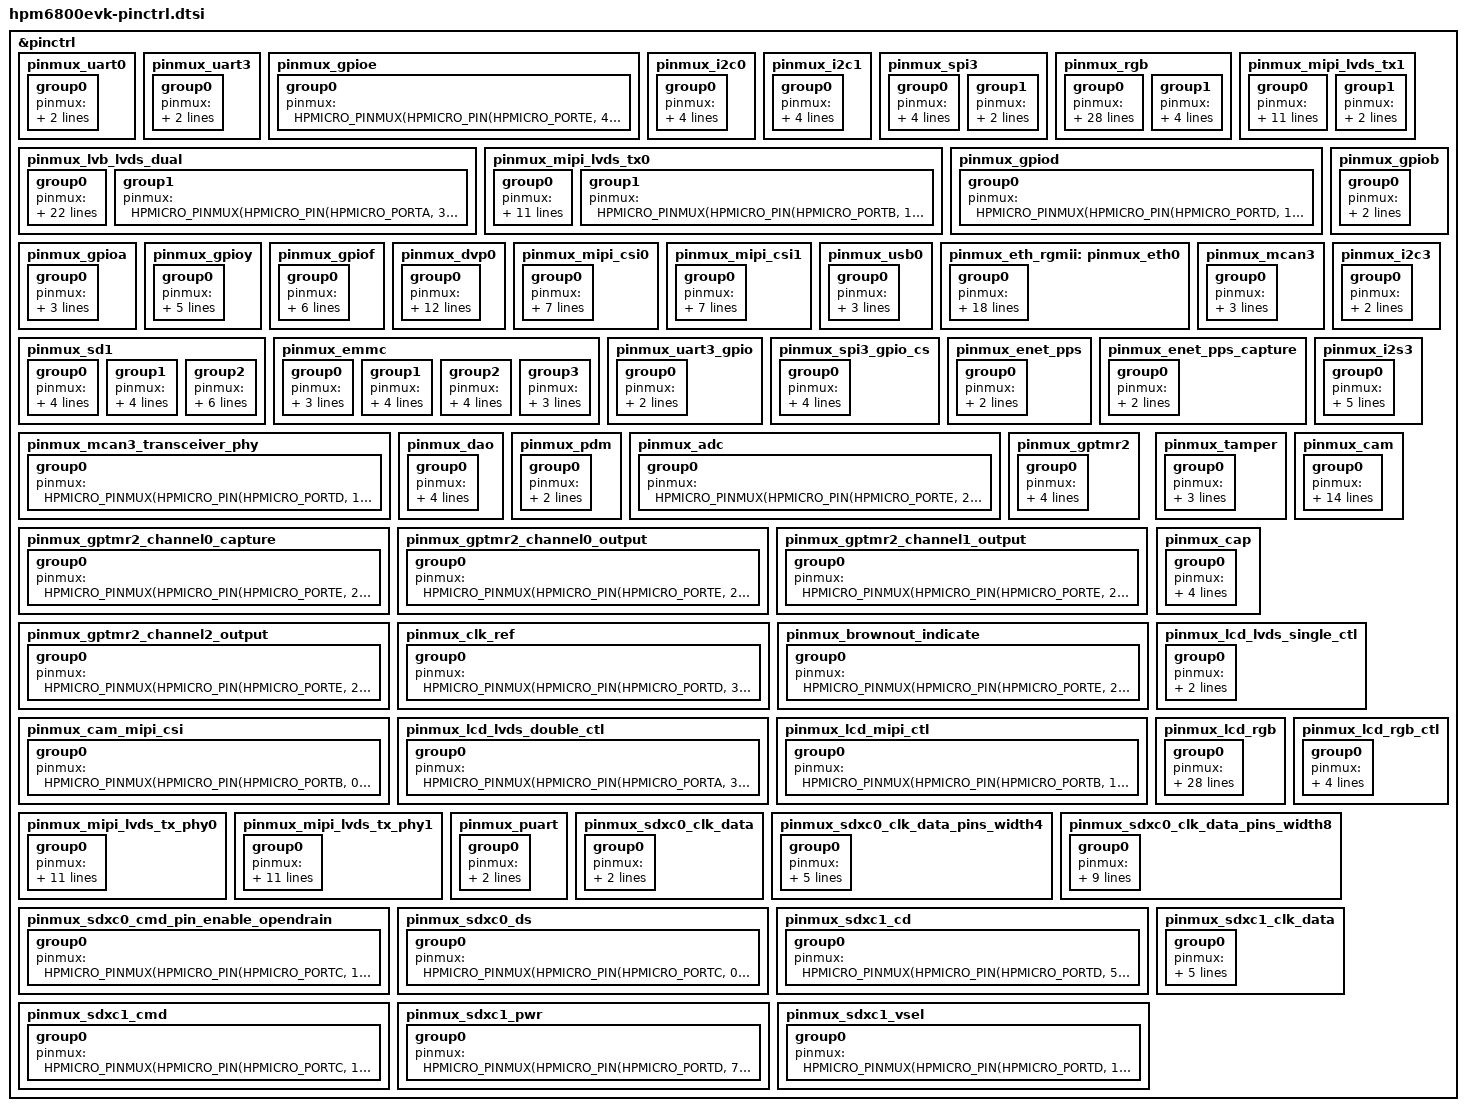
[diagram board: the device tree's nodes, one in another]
/*
* Copyright 2024-2026 HPMicro
* SPDX-License-Identifier: Apache-2.0
*/

#include "dt-bindings/pinctrl/hpmicro-pinctrl-common.h"

&pinctrl {
	pinmux_uart0: pinmux_uart0 {
		group0 {
			pinmux = <HPMICRO_PINMUX(HPMICRO_PIN(HPMICRO_PORTA, 0), IOC_TYPE_IOC, 0, 2)>,
				<HPMICRO_PINMUX(HPMICRO_PIN(HPMICRO_PORTA, 1), IOC_TYPE_IOC, 0, 2)>;
		};
	};

	pinmux_uart3: pinmux_uart3 {
		group0 {
			pinmux = <HPMICRO_PINMUX(HPMICRO_PIN(HPMICRO_PORTE, 14), IOC_TYPE_IOC, 0, 2)>,
				<HPMICRO_PINMUX(HPMICRO_PIN(HPMICRO_PORTE, 15), IOC_TYPE_IOC, 0, 2)>;
		};
	};

	pinmux_gpioe: pinmux_gpioe {
		group0 {
			pinmux = <HPMICRO_PINMUX(HPMICRO_PIN(HPMICRO_PORTE, 4), IOC_TYPE_IOC, 0, 0)>;
		};
	};

	pinmux_i2c0: pinmux_i2c0 {
		group0 {
			pinmux = <HPMICRO_PINMUX(HPMICRO_PIN(HPMICRO_PORTF, 9), IOC_TYPE_IOC, 0, 4)>,
				<HPMICRO_PINMUX(HPMICRO_PIN(HPMICRO_PORTF, 8), IOC_TYPE_IOC, 0, 4)>;
			drive-open-drain;
			input-enable;
		};
	};

	pinmux_i2c1: pinmux_i2c1 {
		group0 {
			pinmux = <HPMICRO_PINMUX(HPMICRO_PIN(HPMICRO_PORTE, 12), IOC_TYPE_IOC, 0, 4)>,
				<HPMICRO_PINMUX(HPMICRO_PIN(HPMICRO_PORTE, 13), IOC_TYPE_IOC, 0, 4)>;
			drive-open-drain;
			input-enable;
		};
	};

	pinmux_spi3: pinmux_spi3 {
		group0 {
			pinmux = <HPMICRO_PINMUX(HPMICRO_PIN(HPMICRO_PORTE, 5), IOC_TYPE_IOC, 0, 5)>,
				<HPMICRO_PINMUX(HPMICRO_PIN(HPMICRO_PORTE, 6), IOC_TYPE_IOC, 0, 5)>,
				<HPMICRO_PINMUX(HPMICRO_PIN(HPMICRO_PORTE, 7), IOC_TYPE_IOC, 0, 5)>;
			input-enable;
		};

		group1 {
			pinmux = <HPMICRO_PINMUX(HPMICRO_PIN(HPMICRO_PORTE, 4), IOC_TYPE_IOC, 0, 0)>;
			bias-pull-up;
		};
	};

	pinmux_rgb: pinmux_rgb {
		group0 {
			pinmux = <HPMICRO_PINMUX(HPMICRO_PIN(HPMICRO_PORTA, 10), IOC_TYPE_IOC, 0, 20)>,
				<HPMICRO_PINMUX(HPMICRO_PIN(HPMICRO_PORTA, 11), IOC_TYPE_IOC, 0, 20)>,
				<HPMICRO_PINMUX(HPMICRO_PIN(HPMICRO_PORTA, 12), IOC_TYPE_IOC, 0, 20)>,
				<HPMICRO_PINMUX(HPMICRO_PIN(HPMICRO_PORTA, 13), IOC_TYPE_IOC, 0, 20)>,
				<HPMICRO_PINMUX(HPMICRO_PIN(HPMICRO_PORTA, 15), IOC_TYPE_IOC, 0, 20)>,
				<HPMICRO_PINMUX(HPMICRO_PIN(HPMICRO_PORTA, 16), IOC_TYPE_IOC, 0, 20)>,
				<HPMICRO_PINMUX(HPMICRO_PIN(HPMICRO_PORTA, 17), IOC_TYPE_IOC, 0, 20)>,
				<HPMICRO_PINMUX(HPMICRO_PIN(HPMICRO_PORTA, 18), IOC_TYPE_IOC, 0, 20)>,
				<HPMICRO_PINMUX(HPMICRO_PIN(HPMICRO_PORTA, 19), IOC_TYPE_IOC, 0, 20)>,
				<HPMICRO_PINMUX(HPMICRO_PIN(HPMICRO_PORTA, 20), IOC_TYPE_IOC, 0, 20)>,
				<HPMICRO_PINMUX(HPMICRO_PIN(HPMICRO_PORTA, 28), IOC_TYPE_IOC, 0, 20)>,
				<HPMICRO_PINMUX(HPMICRO_PIN(HPMICRO_PORTA, 30), IOC_TYPE_IOC, 0, 20)>,
				<HPMICRO_PINMUX(HPMICRO_PIN(HPMICRO_PORTA, 31), IOC_TYPE_IOC, 0, 20)>,
				<HPMICRO_PINMUX(HPMICRO_PIN(HPMICRO_PORTB, 0), IOC_TYPE_IOC, 0, 20)>,
				<HPMICRO_PINMUX(HPMICRO_PIN(HPMICRO_PORTB, 1), IOC_TYPE_IOC, 0, 20)>,
				<HPMICRO_PINMUX(HPMICRO_PIN(HPMICRO_PORTB, 2), IOC_TYPE_IOC, 0, 20)>,
				<HPMICRO_PINMUX(HPMICRO_PIN(HPMICRO_PORTB, 3), IOC_TYPE_IOC, 0, 20)>,
				<HPMICRO_PINMUX(HPMICRO_PIN(HPMICRO_PORTB, 4), IOC_TYPE_IOC, 0, 20)>,
				<HPMICRO_PINMUX(HPMICRO_PIN(HPMICRO_PORTB, 5), IOC_TYPE_IOC, 0, 20)>,
				<HPMICRO_PINMUX(HPMICRO_PIN(HPMICRO_PORTB, 6), IOC_TYPE_IOC, 0, 20)>,
				<HPMICRO_PINMUX(HPMICRO_PIN(HPMICRO_PORTB, 7), IOC_TYPE_IOC, 0, 20)>,
				<HPMICRO_PINMUX(HPMICRO_PIN(HPMICRO_PORTB, 8), IOC_TYPE_IOC, 0, 20)>,
				<HPMICRO_PINMUX(HPMICRO_PIN(HPMICRO_PORTB, 9), IOC_TYPE_IOC, 0, 20)>,
				<HPMICRO_PINMUX(HPMICRO_PIN(HPMICRO_PORTB, 10), IOC_TYPE_IOC, 0, 20)>,
				<HPMICRO_PINMUX(HPMICRO_PIN(HPMICRO_PORTB, 11), IOC_TYPE_IOC, 0, 20)>,
				<HPMICRO_PINMUX(HPMICRO_PIN(HPMICRO_PORTB, 12), IOC_TYPE_IOC, 0, 20)>,
				<HPMICRO_PINMUX(HPMICRO_PIN(HPMICRO_PORTB, 13), IOC_TYPE_IOC, 0, 20)>,
				<HPMICRO_PINMUX(HPMICRO_PIN(HPMICRO_PORTB, 14), IOC_TYPE_IOC, 0, 20)>;
		};

		group1 {
			pinmux = <HPMICRO_PINMUX(HPMICRO_PIN(HPMICRO_PORTA, 9), IOC_TYPE_IOC, 0, 0)>,
				<HPMICRO_PINMUX(HPMICRO_PIN(HPMICRO_PORTA, 14), IOC_TYPE_IOC, 0, 0)>,
				<HPMICRO_PINMUX(HPMICRO_PIN(HPMICRO_PORTY, 5), IOC_TYPE_IOC, 0, 0)>,
				<HPMICRO_PINMUX(HPMICRO_PIN(HPMICRO_PORTY, 5), IOC_TYPE_PIOC, 0, 3)>;
		};
	};

	pinmux_lvb_lvds_dual: pinmux_lvb_lvds_dual {
		group0 {
			pinmux = <HPMICRO_PINMUX(HPMICRO_PIN(HPMICRO_PORTB, 4), IOC_TYPE_IOC, 1, 0)>,
				<HPMICRO_PINMUX(HPMICRO_PIN(HPMICRO_PORTB, 5), IOC_TYPE_IOC, 1, 0)>,
				<HPMICRO_PINMUX(HPMICRO_PIN(HPMICRO_PORTB, 6), IOC_TYPE_IOC, 1, 0)>,
				<HPMICRO_PINMUX(HPMICRO_PIN(HPMICRO_PORTB, 7), IOC_TYPE_IOC, 1, 0)>,
				<HPMICRO_PINMUX(HPMICRO_PIN(HPMICRO_PORTB, 8), IOC_TYPE_IOC, 1, 0)>,
				<HPMICRO_PINMUX(HPMICRO_PIN(HPMICRO_PORTB, 9), IOC_TYPE_IOC, 1, 0)>,
				<HPMICRO_PINMUX(HPMICRO_PIN(HPMICRO_PORTB, 10), IOC_TYPE_IOC, 1, 0)>,
				<HPMICRO_PINMUX(HPMICRO_PIN(HPMICRO_PORTB, 11), IOC_TYPE_IOC, 1, 0)>,
				<HPMICRO_PINMUX(HPMICRO_PIN(HPMICRO_PORTB, 12), IOC_TYPE_IOC, 1, 0)>,
				<HPMICRO_PINMUX(HPMICRO_PIN(HPMICRO_PORTB, 13), IOC_TYPE_IOC, 1, 0)>,
				<HPMICRO_PINMUX(HPMICRO_PIN(HPMICRO_PORTB, 14), IOC_TYPE_IOC, 1, 0)>,
				<HPMICRO_PINMUX(HPMICRO_PIN(HPMICRO_PORTB, 22), IOC_TYPE_IOC, 1, 0)>,
				<HPMICRO_PINMUX(HPMICRO_PIN(HPMICRO_PORTB, 23), IOC_TYPE_IOC, 1, 0)>,
				<HPMICRO_PINMUX(HPMICRO_PIN(HPMICRO_PORTB, 24), IOC_TYPE_IOC, 1, 0)>,
				<HPMICRO_PINMUX(HPMICRO_PIN(HPMICRO_PORTB, 25), IOC_TYPE_IOC, 1, 0)>,
				<HPMICRO_PINMUX(HPMICRO_PIN(HPMICRO_PORTB, 26), IOC_TYPE_IOC, 1, 0)>,
				<HPMICRO_PINMUX(HPMICRO_PIN(HPMICRO_PORTB, 27), IOC_TYPE_IOC, 1, 0)>,
				<HPMICRO_PINMUX(HPMICRO_PIN(HPMICRO_PORTB, 28), IOC_TYPE_IOC, 1, 0)>,
				<HPMICRO_PINMUX(HPMICRO_PIN(HPMICRO_PORTB, 29), IOC_TYPE_IOC, 1, 0)>,
				<HPMICRO_PINMUX(HPMICRO_PIN(HPMICRO_PORTB, 30), IOC_TYPE_IOC, 1, 0)>,
				<HPMICRO_PINMUX(HPMICRO_PIN(HPMICRO_PORTB, 31), IOC_TYPE_IOC, 1, 0)>,
				<HPMICRO_PINMUX(HPMICRO_PIN(HPMICRO_PORTB, 15), IOC_TYPE_IOC, 1, 0)>;
		};

		group1 {
			pinmux = <HPMICRO_PINMUX(HPMICRO_PIN(HPMICRO_PORTA, 31), IOC_TYPE_IOC, 0, 0)>;
		};
	};

	pinmux_mipi_lvds_tx1: pinmux_mipi_lvds_tx1 {
		group0 {
			pinmux = <HPMICRO_PINMUX(HPMICRO_PIN(HPMICRO_PORTB, 22), IOC_TYPE_IOC, 1, 0)>,
				<HPMICRO_PINMUX(HPMICRO_PIN(HPMICRO_PORTB, 23), IOC_TYPE_IOC, 1, 0)>,
				<HPMICRO_PINMUX(HPMICRO_PIN(HPMICRO_PORTB, 24), IOC_TYPE_IOC, 1, 0)>,
				<HPMICRO_PINMUX(HPMICRO_PIN(HPMICRO_PORTB, 25), IOC_TYPE_IOC, 1, 0)>,
				<HPMICRO_PINMUX(HPMICRO_PIN(HPMICRO_PORTB, 26), IOC_TYPE_IOC, 1, 0)>,
				<HPMICRO_PINMUX(HPMICRO_PIN(HPMICRO_PORTB, 27), IOC_TYPE_IOC, 1, 0)>,
				<HPMICRO_PINMUX(HPMICRO_PIN(HPMICRO_PORTB, 28), IOC_TYPE_IOC, 1, 0)>,
				<HPMICRO_PINMUX(HPMICRO_PIN(HPMICRO_PORTB, 29), IOC_TYPE_IOC, 1, 0)>,
				<HPMICRO_PINMUX(HPMICRO_PIN(HPMICRO_PORTB, 30), IOC_TYPE_IOC, 1, 0)>,
				<HPMICRO_PINMUX(HPMICRO_PIN(HPMICRO_PORTB, 31), IOC_TYPE_IOC, 1, 0)>,
				<HPMICRO_PINMUX(HPMICRO_PIN(HPMICRO_PORTB, 15), IOC_TYPE_IOC, 1, 0)>;
		};

		group1 {
			pinmux = <HPMICRO_PINMUX(HPMICRO_PIN(HPMICRO_PORTA, 30), IOC_TYPE_IOC, 0, 0)>,
				<HPMICRO_PINMUX(HPMICRO_PIN(HPMICRO_PORTA, 31), IOC_TYPE_IOC, 0, 0)>;
		};
	};

	pinmux_mipi_lvds_tx0: pinmux_mipi_lvds_tx0 {
		group0 {
			pinmux = <HPMICRO_PINMUX(HPMICRO_PIN(HPMICRO_PORTB, 4), IOC_TYPE_IOC, 1, 0)>,
				<HPMICRO_PINMUX(HPMICRO_PIN(HPMICRO_PORTB, 5), IOC_TYPE_IOC, 1, 0)>,
				<HPMICRO_PINMUX(HPMICRO_PIN(HPMICRO_PORTB, 6), IOC_TYPE_IOC, 1, 0)>,
				<HPMICRO_PINMUX(HPMICRO_PIN(HPMICRO_PORTB, 7), IOC_TYPE_IOC, 1, 0)>,
				<HPMICRO_PINMUX(HPMICRO_PIN(HPMICRO_PORTB, 8), IOC_TYPE_IOC, 1, 0)>,
				<HPMICRO_PINMUX(HPMICRO_PIN(HPMICRO_PORTB, 9), IOC_TYPE_IOC, 1, 0)>,
				<HPMICRO_PINMUX(HPMICRO_PIN(HPMICRO_PORTB, 10), IOC_TYPE_IOC, 1, 0)>,
				<HPMICRO_PINMUX(HPMICRO_PIN(HPMICRO_PORTB, 11), IOC_TYPE_IOC, 1, 0)>,
				<HPMICRO_PINMUX(HPMICRO_PIN(HPMICRO_PORTB, 12), IOC_TYPE_IOC, 1, 0)>,
				<HPMICRO_PINMUX(HPMICRO_PIN(HPMICRO_PORTB, 13), IOC_TYPE_IOC, 1, 0)>,
				<HPMICRO_PINMUX(HPMICRO_PIN(HPMICRO_PORTB, 14), IOC_TYPE_IOC, 1, 0)>;
		};

		group1 {
			pinmux = <HPMICRO_PINMUX(HPMICRO_PIN(HPMICRO_PORTB, 1), IOC_TYPE_IOC, 0, 0)>;
		};
	};

	pinmux_gpiod: pinmux_gpiod {
		group0 {
			pinmux = <HPMICRO_PINMUX(HPMICRO_PIN(HPMICRO_PORTD, 18), IOC_TYPE_IOC, 0, 0)>;
		};
	};

	pinmux_gpiob: pinmux_gpiob {
		group0 {
			pinmux = <HPMICRO_PINMUX(HPMICRO_PIN(HPMICRO_PORTB, 0), IOC_TYPE_IOC, 0, 0)>;
			bias-pull-up;
		};
	};

	pinmux_gpioa: pinmux_gpioa {
		group0 {
			pinmux = <HPMICRO_PINMUX(HPMICRO_PIN(HPMICRO_PORTA, 21), IOC_TYPE_IOC, 0, 0)>,
				<HPMICRO_PINMUX(HPMICRO_PIN(HPMICRO_PORTA, 22), IOC_TYPE_IOC, 0, 0)>;
			bias-pull-down;
		};
	};

	pinmux_gpioy: pinmux_gpioy {
		group0 {
			pinmux = <HPMICRO_PINMUX(HPMICRO_PIN(HPMICRO_PORTY, 6), IOC_TYPE_IOC, 0, 0)>,
				<HPMICRO_PINMUX(HPMICRO_PIN(HPMICRO_PORTY, 6), IOC_TYPE_PIOC, 0, 3)>,
				<HPMICRO_PINMUX(HPMICRO_PIN(HPMICRO_PORTY, 7), IOC_TYPE_IOC, 0, 0)>,
				<HPMICRO_PINMUX(HPMICRO_PIN(HPMICRO_PORTY, 7), IOC_TYPE_PIOC, 0, 3)>;
			bias-pull-up;
		};
	};

	pinmux_gpiof: pinmux_gpiof {
		group0 {
			pinmux = <HPMICRO_PINMUX(HPMICRO_PIN(HPMICRO_PORTF, 6), IOC_TYPE_IOC, 0, 0)>,
				<HPMICRO_PINMUX(HPMICRO_PIN(HPMICRO_PORTF, 7), IOC_TYPE_IOC, 0, 0)>;
			bias-pull-up;
			input-enable;
			keeper-capability-disable;
			input-schmitt-enable; 
		};
	};

	pinmux_dvp0: pinmux_dvp0 {
		group0 {
			pinmux = <HPMICRO_PINMUX(HPMICRO_PIN(HPMICRO_PORTB, 20), IOC_TYPE_IOC, 0, 22)>,
				<HPMICRO_PINMUX(HPMICRO_PIN(HPMICRO_PORTB, 21), IOC_TYPE_IOC, 0, 22)>,
				<HPMICRO_PINMUX(HPMICRO_PIN(HPMICRO_PORTA, 23), IOC_TYPE_IOC, 0, 22)>,
				<HPMICRO_PINMUX(HPMICRO_PIN(HPMICRO_PORTA, 24), IOC_TYPE_IOC, 0, 22)>,
				<HPMICRO_PINMUX(HPMICRO_PIN(HPMICRO_PORTA, 25), IOC_TYPE_IOC, 0, 22)>,
				<HPMICRO_PINMUX(HPMICRO_PIN(HPMICRO_PORTA, 26), IOC_TYPE_IOC, 0, 22)>,
				<HPMICRO_PINMUX(HPMICRO_PIN(HPMICRO_PORTA, 27), IOC_TYPE_IOC, 0, 22)>,
				<HPMICRO_PINMUX(HPMICRO_PIN(HPMICRO_PORTA, 29), IOC_TYPE_IOC, 0, 22)>,
				<HPMICRO_PINMUX(HPMICRO_PIN(HPMICRO_PORTB, 16), IOC_TYPE_IOC, 0, 22)>,
				<HPMICRO_PINMUX(HPMICRO_PIN(HPMICRO_PORTB, 17), IOC_TYPE_IOC, 0, 22)>,
				<HPMICRO_PINMUX(HPMICRO_PIN(HPMICRO_PORTB, 18), IOC_TYPE_IOC, 0, 22)>,
				<HPMICRO_PINMUX(HPMICRO_PIN(HPMICRO_PORTB, 19), IOC_TYPE_IOC, 0, 22)>;
		};
	};

	pinmux_mipi_csi0: pinmux_mipi_csi0 {
		group0 {
			pinmux = <HPMICRO_PINMUX(HPMICRO_PIN(HPMICRO_PORTA, 30), IOC_TYPE_IOC, 1, 0)>,
				<HPMICRO_PINMUX(HPMICRO_PIN(HPMICRO_PORTA, 31), IOC_TYPE_IOC, 1, 0)>,
				<HPMICRO_PINMUX(HPMICRO_PIN(HPMICRO_PORTA, 28), IOC_TYPE_IOC, 1, 0)>,
				<HPMICRO_PINMUX(HPMICRO_PIN(HPMICRO_PORTB, 0), IOC_TYPE_IOC, 1, 0)>,
				<HPMICRO_PINMUX(HPMICRO_PIN(HPMICRO_PORTB, 1), IOC_TYPE_IOC, 1, 0)>,
				<HPMICRO_PINMUX(HPMICRO_PIN(HPMICRO_PORTB, 2), IOC_TYPE_IOC, 1, 0)>,
				<HPMICRO_PINMUX(HPMICRO_PIN(HPMICRO_PORTB, 3), IOC_TYPE_IOC, 1, 0)>;
		};
	};

	pinmux_mipi_csi1: pinmux_mipi_csi1 {
		group0 {
			pinmux =  <HPMICRO_PINMUX(HPMICRO_PIN(HPMICRO_PORTA, 29), IOC_TYPE_IOC, 1, 0)>,
				<HPMICRO_PINMUX(HPMICRO_PIN(HPMICRO_PORTB, 16), IOC_TYPE_IOC, 1, 0)>,
				<HPMICRO_PINMUX(HPMICRO_PIN(HPMICRO_PORTB, 17), IOC_TYPE_IOC, 1, 0)>,
				<HPMICRO_PINMUX(HPMICRO_PIN(HPMICRO_PORTB, 18), IOC_TYPE_IOC, 1, 0)>,
				<HPMICRO_PINMUX(HPMICRO_PIN(HPMICRO_PORTB, 19), IOC_TYPE_IOC, 1, 0)>,
				<HPMICRO_PINMUX(HPMICRO_PIN(HPMICRO_PORTB, 20), IOC_TYPE_IOC, 1, 0)>,
				<HPMICRO_PINMUX(HPMICRO_PIN(HPMICRO_PORTB, 21), IOC_TYPE_IOC, 1, 0)>;
		};
	};

	pinmux_usb0: pinmux_usb0 {
		group0 {
			pinmux = <HPMICRO_PINMUX(HPMICRO_PIN(HPMICRO_PORTF, 4), IOC_TYPE_IOC, 0, 24)>,
				<HPMICRO_PINMUX(HPMICRO_PIN(HPMICRO_PORTF, 3), IOC_TYPE_IOC, 0, 24)>,
				<HPMICRO_PINMUX(HPMICRO_PIN(HPMICRO_PORTF, 0), IOC_TYPE_IOC, 0, 24)>;
		};
	};

	pinmux_eth_rgmii: pinmux_eth0 {
		group0 {
			pinmux = <HPMICRO_PINMUX(HPMICRO_PIN(HPMICRO_PORTD, 2), IOC_TYPE_IOC, 0, 18)>,
				<HPMICRO_PINMUX(HPMICRO_PIN(HPMICRO_PORTD, 3), IOC_TYPE_IOC, 0, 18)>,
				<HPMICRO_PINMUX(HPMICRO_PIN(HPMICRO_PORTC, 29), IOC_TYPE_IOC, 0, 18)>,
				<HPMICRO_PINMUX(HPMICRO_PIN(HPMICRO_PORTC, 28), IOC_TYPE_IOC, 0, 18)>,
				<HPMICRO_PINMUX(HPMICRO_PIN(HPMICRO_PORTC, 24), IOC_TYPE_IOC, 0, 18)>,
				<HPMICRO_PINMUX(HPMICRO_PIN(HPMICRO_PORTC, 25), IOC_TYPE_IOC, 0, 18)>,
				<HPMICRO_PINMUX(HPMICRO_PIN(HPMICRO_PORTC, 26), IOC_TYPE_IOC, 0, 18)>,
				<HPMICRO_PINMUX(HPMICRO_PIN(HPMICRO_PORTC, 27), IOC_TYPE_IOC, 0, 18)>,
				<HPMICRO_PINMUX(HPMICRO_PIN(HPMICRO_PORTC, 22), IOC_TYPE_IOC, 0, 18)>,
				<HPMICRO_PINMUX(HPMICRO_PIN(HPMICRO_PORTC, 23), IOC_TYPE_IOC, 0, 18)>,
				<HPMICRO_PINMUX(HPMICRO_PIN(HPMICRO_PORTC, 19), IOC_TYPE_IOC, 0, 18)>,
				<HPMICRO_PINMUX(HPMICRO_PIN(HPMICRO_PORTC, 18), IOC_TYPE_IOC, 0, 18)>,
				<HPMICRO_PINMUX(HPMICRO_PIN(HPMICRO_PORTC, 20), IOC_TYPE_IOC, 0, 18)>,
				<HPMICRO_PINMUX(HPMICRO_PIN(HPMICRO_PORTC, 21), IOC_TYPE_IOC, 0, 18)>;
			input-schmitt-enable;
			slew-rate = "fast";
			slew-pd = "100M";
			drive-strength = "r011";
		};
	};

	pinmux_mcan3: pinmux_mcan3 {
		group0 {
			pinmux = <HPMICRO_PINMUX(HPMICRO_PIN(HPMICRO_PORTD, 15), IOC_TYPE_IOC, 0, 7)>,
				<HPMICRO_PINMUX(HPMICRO_PIN(HPMICRO_PORTD, 14), IOC_TYPE_IOC, 0, 7)>,
				<HPMICRO_PINMUX(HPMICRO_PIN(HPMICRO_PORTD, 13), IOC_TYPE_IOC, 0, 7)>;
		};
	};

	pinmux_sd1: pinmux_sd1 {
		group0 {
			pinmux = <HPMICRO_PINMUX(HPMICRO_PIN(HPMICRO_PORTC, 13), IOC_TYPE_IOC, 0, 17)>;
			bias-pull-up;
			input-enable;
			drive-strength = "r110";
		};

		group1 {
			pinmux = <HPMICRO_PINMUX(HPMICRO_PIN(HPMICRO_PORTC, 16), IOC_TYPE_IOC, 0, 17)>;
			bias-pull-up;
			input-enable;
			drive-strength = "r111";
		};

		group2 {
			pinmux = <HPMICRO_PINMUX(HPMICRO_PIN(HPMICRO_PORTC, 17), IOC_TYPE_IOC, 0, 17)>,
				<HPMICRO_PINMUX(HPMICRO_PIN(HPMICRO_PORTC, 15), IOC_TYPE_IOC, 0, 17)>,
				<HPMICRO_PINMUX(HPMICRO_PIN(HPMICRO_PORTC, 14), IOC_TYPE_IOC, 0, 17)>,
				<HPMICRO_PINMUX(HPMICRO_PIN(HPMICRO_PORTC, 12), IOC_TYPE_IOC, 0, 17)>;
			bias-pull-up;
			drive-strength = "r111";
		};
	};

	pinmux_emmc: pinmux_emmc {
		group0 {
			pinmux = <HPMICRO_PINMUX(HPMICRO_PIN(HPMICRO_PORTC, 0), IOC_TYPE_IOC, 0, 17)>;
			bias-pull-up;
			input-enable;
		};

		group1 {
			pinmux = <HPMICRO_PINMUX(HPMICRO_PIN(HPMICRO_PORTC, 1), IOC_TYPE_IOC, 0, 17)>;
			bias-pull-up;
			input-enable;
			drive-strength = "r111";
		};

		group2 {
			pinmux = <HPMICRO_PINMUX(HPMICRO_PIN(HPMICRO_PORTC, 2), IOC_TYPE_IOC, 0, 17)>;
			bias-pull-up;
			input-enable;
			drive-strength = "r111";
		};

		group3 {
			pinmux = <HPMICRO_PINMUX(HPMICRO_PIN(HPMICRO_PORTC, 6), IOC_TYPE_IOC, 0, 17)>;
			bias-pull-up;
			drive-strength = "r111";
		};
	};

	pinmux_uart3_gpio: pinmux_uart3_gpio {
		group0 {
			pinmux = <HPMICRO_PINMUX(HPMICRO_PIN(HPMICRO_PORTE, 14), IOC_TYPE_IOC, 0, 0)>,
				<HPMICRO_PINMUX(HPMICRO_PIN(HPMICRO_PORTE, 15), IOC_TYPE_IOC, 0, 0)>;
		};
	};

	pinmux_i2c3: pinmux_i2c3 {
		group0 {
			pinmux = <HPMICRO_PINMUX(HPMICRO_PIN(HPMICRO_PORTD, 28), IOC_TYPE_IOC, 0, 4)>,
				<HPMICRO_PINMUX(HPMICRO_PIN(HPMICRO_PORTD, 29), IOC_TYPE_IOC, 0, 4)>;
		};
	};

	pinmux_spi3_gpio_cs: pinmux_spi3_gpio_cs {
		group0 {
			pinmux = <HPMICRO_PINMUX(HPMICRO_PIN(HPMICRO_PORTE, 5), IOC_TYPE_IOC, 0, 5)>,
				<HPMICRO_PINMUX(HPMICRO_PIN(HPMICRO_PORTE, 6), IOC_TYPE_IOC, 0, 5)>,
				<HPMICRO_PINMUX(HPMICRO_PIN(HPMICRO_PORTE, 7), IOC_TYPE_IOC, 0, 5)>,
				<HPMICRO_PINMUX(HPMICRO_PIN(HPMICRO_PORTE, 4), IOC_TYPE_IOC, 0, 0)>;
		};
	};

	pinmux_enet_pps: pinmux_enet_pps {
		group0 {
			pinmux = <HPMICRO_PINMUX(HPMICRO_PIN(HPMICRO_PORTD, 31), IOC_TYPE_IOC, 0, 19)>,
				<HPMICRO_PINMUX(HPMICRO_PIN(HPMICRO_PORTE, 10), IOC_TYPE_IOC, 0, 19)>;
		};
	};

	pinmux_enet_pps_capture: pinmux_enet_pps_capture {
		group0 {
			pinmux = <HPMICRO_PINMUX(HPMICRO_PIN(HPMICRO_PORTE, 17), IOC_TYPE_IOC, 0, 19)>,
				<HPMICRO_PINMUX(HPMICRO_PIN(HPMICRO_PORTE, 19), IOC_TYPE_IOC, 0, 19)>;
		};
	};

	pinmux_mcan3_transceiver_phy: pinmux_mcan3_transceiver_phy {
		group0 {
			pinmux = <HPMICRO_PINMUX(HPMICRO_PIN(HPMICRO_PORTD, 13), IOC_TYPE_IOC, 0, 0)>;
		};
	};

	pinmux_i2s3: pinmux_i2s3 {
		group0 {
			pinmux = <HPMICRO_PINMUX(HPMICRO_PIN(HPMICRO_PORTD, 30), IOC_TYPE_IOC, 0, 8)>,
				<HPMICRO_PINMUX(HPMICRO_PIN(HPMICRO_PORTD, 24), IOC_TYPE_IOC, 0, 8)>,
				<HPMICRO_PINMUX(HPMICRO_PIN(HPMICRO_PORTD, 25), IOC_TYPE_IOC, 0, 8)>,
				<HPMICRO_PINMUX(HPMICRO_PIN(HPMICRO_PORTD, 27), IOC_TYPE_IOC, 0, 8)>,
				<HPMICRO_PINMUX(HPMICRO_PIN(HPMICRO_PORTD, 23), IOC_TYPE_IOC, 0, 8)>;
		};
	};

	pinmux_dao: pinmux_dao {
		group0 {
			pinmux = <HPMICRO_PINMUX(HPMICRO_PIN(HPMICRO_PORTC, 31), IOC_TYPE_IOC, 0, 10)>,
				<HPMICRO_PINMUX(HPMICRO_PIN(HPMICRO_PORTC, 30), IOC_TYPE_IOC, 0, 10)>,
				<HPMICRO_PINMUX(HPMICRO_PIN(HPMICRO_PORTD, 1), IOC_TYPE_IOC, 0, 10)>,
				<HPMICRO_PINMUX(HPMICRO_PIN(HPMICRO_PORTD, 0), IOC_TYPE_IOC, 0, 10)>;
		};
	};

	pinmux_pdm: pinmux_pdm {
		group0 {
			pinmux = <HPMICRO_PINMUX(HPMICRO_PIN(HPMICRO_PORTE, 0), IOC_TYPE_IOC, 0, 10)>,
				<HPMICRO_PINMUX(HPMICRO_PIN(HPMICRO_PORTE, 1), IOC_TYPE_IOC, 0, 10)>;
		};
	};

	pinmux_adc: pinmux_adc {
		group0 {
			pinmux = <HPMICRO_PINMUX(HPMICRO_PIN(HPMICRO_PORTE, 24), IOC_TYPE_IOC, 1, 0)>;
		};
	};

	pinmux_gptmr2: pinmux_gptmr2 {
		group0 {
			pinmux = <HPMICRO_PINMUX(HPMICRO_PIN(HPMICRO_PORTE, 22), IOC_TYPE_IOC, 0, 1)>,
				<HPMICRO_PINMUX(HPMICRO_PIN(HPMICRO_PORTE, 23), IOC_TYPE_IOC, 0, 1)>,
				<HPMICRO_PINMUX(HPMICRO_PIN(HPMICRO_PORTE, 24), IOC_TYPE_IOC, 0, 1)>,
				<HPMICRO_PINMUX(HPMICRO_PIN(HPMICRO_PORTE, 26), IOC_TYPE_IOC, 0, 1)>;
		};
	};

	pinmux_gptmr2_channel0_capture: pinmux_gptmr2_channel0_capture {
		group0 {
			pinmux = <HPMICRO_PINMUX(HPMICRO_PIN(HPMICRO_PORTE, 22), IOC_TYPE_IOC, 0, 1)>;
		};
	};

	pinmux_gptmr2_channel0_output: pinmux_gptmr2_channel0_output {
		group0 {
			pinmux = <HPMICRO_PINMUX(HPMICRO_PIN(HPMICRO_PORTE, 23), IOC_TYPE_IOC, 0, 1)>;
		};
	};

	pinmux_gptmr2_channel1_output: pinmux_gptmr2_channel1_output {
		group0 {
			pinmux = <HPMICRO_PINMUX(HPMICRO_PIN(HPMICRO_PORTE, 24), IOC_TYPE_IOC, 0, 1)>;
		};
	};

	pinmux_gptmr2_channel2_output: pinmux_gptmr2_channel2_output {
		group0 {
			pinmux = <HPMICRO_PINMUX(HPMICRO_PIN(HPMICRO_PORTE, 26), IOC_TYPE_IOC, 0, 1)>;
		};
	};

	pinmux_tamper: pinmux_tamper {
		group0 {
			pinmux = <HPMICRO_PINMUX(HPMICRO_PIN(HPMICRO_PORTZ, 4), IOC_TYPE_BIOC, 0, 2)>,
				<HPMICRO_PINMUX(HPMICRO_PIN(HPMICRO_PORTZ, 5), IOC_TYPE_BIOC, 0, 2)>,
				<HPMICRO_PINMUX(HPMICRO_PIN(HPMICRO_PORTZ, 6), IOC_TYPE_BIOC, 0, 2)>;
		};
	};

	pinmux_clk_ref: pinmux_clk_ref {
		group0 {
			pinmux = <HPMICRO_PINMUX(HPMICRO_PIN(HPMICRO_PORTD, 31), IOC_TYPE_IOC, 0, 24)>;
		};
	};

	pinmux_brownout_indicate: pinmux_brownout_indicate {
		group0 {
			pinmux = <HPMICRO_PINMUX(HPMICRO_PIN(HPMICRO_PORTE, 27), IOC_TYPE_IOC, 0, 0)>;
		};
	};

	pinmux_cam: pinmux_cam {
		group0 {
			pinmux = <HPMICRO_PINMUX(HPMICRO_PIN(HPMICRO_PORTA, 22), IOC_TYPE_IOC, 0, 0)>,
				<HPMICRO_PINMUX(HPMICRO_PIN(HPMICRO_PORTA, 21), IOC_TYPE_IOC, 0, 0)>,
				<HPMICRO_PINMUX(HPMICRO_PIN(HPMICRO_PORTA, 29), IOC_TYPE_IOC, 0, 22)>,
				<HPMICRO_PINMUX(HPMICRO_PIN(HPMICRO_PORTA, 26), IOC_TYPE_IOC, 0, 22)>,
				<HPMICRO_PINMUX(HPMICRO_PIN(HPMICRO_PORTB, 21), IOC_TYPE_IOC, 0, 22)>,
				<HPMICRO_PINMUX(HPMICRO_PIN(HPMICRO_PORTB, 20), IOC_TYPE_IOC, 0, 22)>,
				<HPMICRO_PINMUX(HPMICRO_PIN(HPMICRO_PORTA, 27), IOC_TYPE_IOC, 0, 22)>,
				<HPMICRO_PINMUX(HPMICRO_PIN(HPMICRO_PORTA, 25), IOC_TYPE_IOC, 0, 22)>,
				<HPMICRO_PINMUX(HPMICRO_PIN(HPMICRO_PORTA, 23), IOC_TYPE_IOC, 0, 22)>,
				<HPMICRO_PINMUX(HPMICRO_PIN(HPMICRO_PORTA, 24), IOC_TYPE_IOC, 0, 22)>,
				<HPMICRO_PINMUX(HPMICRO_PIN(HPMICRO_PORTB, 16), IOC_TYPE_IOC, 0, 22)>,
				<HPMICRO_PINMUX(HPMICRO_PIN(HPMICRO_PORTB, 17), IOC_TYPE_IOC, 0, 22)>,
				<HPMICRO_PINMUX(HPMICRO_PIN(HPMICRO_PORTB, 19), IOC_TYPE_IOC, 0, 22)>,
				<HPMICRO_PINMUX(HPMICRO_PIN(HPMICRO_PORTB, 18), IOC_TYPE_IOC, 0, 22)>;
		};
	};

	pinmux_cam_mipi_csi: pinmux_cam_mipi_csi {
		group0 {
			pinmux = <HPMICRO_PINMUX(HPMICRO_PIN(HPMICRO_PORTB, 0), IOC_TYPE_IOC, 0, 0)>;
		};
	};

	pinmux_cap: pinmux_cap {
		group0 {
			pinmux = <HPMICRO_PINMUX(HPMICRO_PIN(HPMICRO_PORTY, 6), IOC_TYPE_IOC, 0, 0)>,
				<HPMICRO_PINMUX(HPMICRO_PIN(HPMICRO_PORTY, 6), IOC_TYPE_PIOC, 0, 3)>,
				<HPMICRO_PINMUX(HPMICRO_PIN(HPMICRO_PORTY, 7), IOC_TYPE_IOC, 0, 0)>,
				<HPMICRO_PINMUX(HPMICRO_PIN(HPMICRO_PORTY, 7), IOC_TYPE_PIOC, 0, 3)>;
		};
	};

	pinmux_lcd_lvds_double_ctl: pinmux_lcd_lvds_double_ctl {
		group0 {
			pinmux = <HPMICRO_PINMUX(HPMICRO_PIN(HPMICRO_PORTA, 31), IOC_TYPE_IOC, 0, 0)>;
		};
	};

	pinmux_lcd_lvds_single_ctl: pinmux_lcd_lvds_single_ctl {
		group0 {
			pinmux = <HPMICRO_PINMUX(HPMICRO_PIN(HPMICRO_PORTA, 30), IOC_TYPE_IOC, 0, 0)>,
				<HPMICRO_PINMUX(HPMICRO_PIN(HPMICRO_PORTA, 31), IOC_TYPE_IOC, 0, 0)>;
		};
	};

	pinmux_lcd_mipi_ctl: pinmux_lcd_mipi_ctl {
		group0 {
			pinmux = <HPMICRO_PINMUX(HPMICRO_PIN(HPMICRO_PORTB, 1), IOC_TYPE_IOC, 0, 0)>;
		};
	};

	pinmux_lcd_rgb: pinmux_lcd_rgb {
		group0 {
			pinmux = <HPMICRO_PINMUX(HPMICRO_PIN(HPMICRO_PORTA, 10), IOC_TYPE_IOC, 0, 20)>,
				<HPMICRO_PINMUX(HPMICRO_PIN(HPMICRO_PORTA, 11), IOC_TYPE_IOC, 0, 20)>,
				<HPMICRO_PINMUX(HPMICRO_PIN(HPMICRO_PORTA, 12), IOC_TYPE_IOC, 0, 20)>,
				<HPMICRO_PINMUX(HPMICRO_PIN(HPMICRO_PORTA, 13), IOC_TYPE_IOC, 0, 20)>,
				<HPMICRO_PINMUX(HPMICRO_PIN(HPMICRO_PORTA, 15), IOC_TYPE_IOC, 0, 20)>,
				<HPMICRO_PINMUX(HPMICRO_PIN(HPMICRO_PORTA, 16), IOC_TYPE_IOC, 0, 20)>,
				<HPMICRO_PINMUX(HPMICRO_PIN(HPMICRO_PORTA, 17), IOC_TYPE_IOC, 0, 20)>,
				<HPMICRO_PINMUX(HPMICRO_PIN(HPMICRO_PORTA, 18), IOC_TYPE_IOC, 0, 20)>,
				<HPMICRO_PINMUX(HPMICRO_PIN(HPMICRO_PORTA, 19), IOC_TYPE_IOC, 0, 20)>,
				<HPMICRO_PINMUX(HPMICRO_PIN(HPMICRO_PORTA, 20), IOC_TYPE_IOC, 0, 20)>,
				<HPMICRO_PINMUX(HPMICRO_PIN(HPMICRO_PORTA, 28), IOC_TYPE_IOC, 0, 20)>,
				<HPMICRO_PINMUX(HPMICRO_PIN(HPMICRO_PORTA, 30), IOC_TYPE_IOC, 0, 20)>,
				<HPMICRO_PINMUX(HPMICRO_PIN(HPMICRO_PORTA, 31), IOC_TYPE_IOC, 0, 20)>,
				<HPMICRO_PINMUX(HPMICRO_PIN(HPMICRO_PORTB, 0), IOC_TYPE_IOC, 0, 20)>,
				<HPMICRO_PINMUX(HPMICRO_PIN(HPMICRO_PORTB, 1), IOC_TYPE_IOC, 0, 20)>,
				<HPMICRO_PINMUX(HPMICRO_PIN(HPMICRO_PORTB, 2), IOC_TYPE_IOC, 0, 20)>,
				<HPMICRO_PINMUX(HPMICRO_PIN(HPMICRO_PORTB, 3), IOC_TYPE_IOC, 0, 20)>,
				<HPMICRO_PINMUX(HPMICRO_PIN(HPMICRO_PORTB, 4), IOC_TYPE_IOC, 0, 20)>,
				<HPMICRO_PINMUX(HPMICRO_PIN(HPMICRO_PORTB, 5), IOC_TYPE_IOC, 0, 20)>,
				<HPMICRO_PINMUX(HPMICRO_PIN(HPMICRO_PORTB, 6), IOC_TYPE_IOC, 0, 20)>,
				<HPMICRO_PINMUX(HPMICRO_PIN(HPMICRO_PORTB, 7), IOC_TYPE_IOC, 0, 20)>,
				<HPMICRO_PINMUX(HPMICRO_PIN(HPMICRO_PORTB, 8), IOC_TYPE_IOC, 0, 20)>,
				<HPMICRO_PINMUX(HPMICRO_PIN(HPMICRO_PORTB, 9), IOC_TYPE_IOC, 0, 20)>,
				<HPMICRO_PINMUX(HPMICRO_PIN(HPMICRO_PORTB, 10), IOC_TYPE_IOC, 0, 20)>,
				<HPMICRO_PINMUX(HPMICRO_PIN(HPMICRO_PORTB, 11), IOC_TYPE_IOC, 0, 20)>,
				<HPMICRO_PINMUX(HPMICRO_PIN(HPMICRO_PORTB, 12), IOC_TYPE_IOC, 0, 20)>,
				<HPMICRO_PINMUX(HPMICRO_PIN(HPMICRO_PORTB, 14), IOC_TYPE_IOC, 0, 20)>,
				<HPMICRO_PINMUX(HPMICRO_PIN(HPMICRO_PORTB, 13), IOC_TYPE_IOC, 0, 20)>;
		};
	};

	pinmux_lcd_rgb_ctl: pinmux_lcd_rgb_ctl {
		group0 {
			pinmux = <HPMICRO_PINMUX(HPMICRO_PIN(HPMICRO_PORTA, 9), IOC_TYPE_IOC, 0, 0)>,
				<HPMICRO_PINMUX(HPMICRO_PIN(HPMICRO_PORTA, 14), IOC_TYPE_IOC, 0, 0)>,
				<HPMICRO_PINMUX(HPMICRO_PIN(HPMICRO_PORTY, 5), IOC_TYPE_IOC, 0, 0)>,
				<HPMICRO_PINMUX(HPMICRO_PIN(HPMICRO_PORTY, 5), IOC_TYPE_PIOC, 0, 3)>;
		};
	};

	pinmux_mipi_lvds_tx_phy0: pinmux_mipi_lvds_tx_phy0 {
		group0 {
			pinmux = <HPMICRO_PINMUX(HPMICRO_PIN(HPMICRO_PORTB, 4), IOC_TYPE_IOC, 1, 0)>,
				<HPMICRO_PINMUX(HPMICRO_PIN(HPMICRO_PORTB, 5), IOC_TYPE_IOC, 1, 0)>,
				<HPMICRO_PINMUX(HPMICRO_PIN(HPMICRO_PORTB, 6), IOC_TYPE_IOC, 1, 0)>,
				<HPMICRO_PINMUX(HPMICRO_PIN(HPMICRO_PORTB, 7), IOC_TYPE_IOC, 1, 0)>,
				<HPMICRO_PINMUX(HPMICRO_PIN(HPMICRO_PORTB, 8), IOC_TYPE_IOC, 1, 0)>,
				<HPMICRO_PINMUX(HPMICRO_PIN(HPMICRO_PORTB, 9), IOC_TYPE_IOC, 1, 0)>,
				<HPMICRO_PINMUX(HPMICRO_PIN(HPMICRO_PORTB, 10), IOC_TYPE_IOC, 1, 0)>,
				<HPMICRO_PINMUX(HPMICRO_PIN(HPMICRO_PORTB, 11), IOC_TYPE_IOC, 1, 0)>,
				<HPMICRO_PINMUX(HPMICRO_PIN(HPMICRO_PORTB, 12), IOC_TYPE_IOC, 1, 0)>,
				<HPMICRO_PINMUX(HPMICRO_PIN(HPMICRO_PORTB, 13), IOC_TYPE_IOC, 1, 0)>,
				<HPMICRO_PINMUX(HPMICRO_PIN(HPMICRO_PORTB, 14), IOC_TYPE_IOC, 1, 0)>;
		};
	};

	pinmux_mipi_lvds_tx_phy1: pinmux_mipi_lvds_tx_phy1 {
		group0 {
			pinmux = <HPMICRO_PINMUX(HPMICRO_PIN(HPMICRO_PORTB, 22), IOC_TYPE_IOC, 1, 0)>,
				<HPMICRO_PINMUX(HPMICRO_PIN(HPMICRO_PORTB, 23), IOC_TYPE_IOC, 1, 0)>,
				<HPMICRO_PINMUX(HPMICRO_PIN(HPMICRO_PORTB, 24), IOC_TYPE_IOC, 1, 0)>,
				<HPMICRO_PINMUX(HPMICRO_PIN(HPMICRO_PORTB, 25), IOC_TYPE_IOC, 1, 0)>,
				<HPMICRO_PINMUX(HPMICRO_PIN(HPMICRO_PORTB, 26), IOC_TYPE_IOC, 1, 0)>,
				<HPMICRO_PINMUX(HPMICRO_PIN(HPMICRO_PORTB, 27), IOC_TYPE_IOC, 1, 0)>,
				<HPMICRO_PINMUX(HPMICRO_PIN(HPMICRO_PORTB, 28), IOC_TYPE_IOC, 1, 0)>,
				<HPMICRO_PINMUX(HPMICRO_PIN(HPMICRO_PORTB, 29), IOC_TYPE_IOC, 1, 0)>,
				<HPMICRO_PINMUX(HPMICRO_PIN(HPMICRO_PORTB, 30), IOC_TYPE_IOC, 1, 0)>,
				<HPMICRO_PINMUX(HPMICRO_PIN(HPMICRO_PORTB, 31), IOC_TYPE_IOC, 1, 0)>,
				<HPMICRO_PINMUX(HPMICRO_PIN(HPMICRO_PORTB, 15), IOC_TYPE_IOC, 1, 0)>;
		};
	};

	pinmux_puart: pinmux_puart {
		group0 {
			pinmux = <HPMICRO_PINMUX(HPMICRO_PIN(HPMICRO_PORTY, 0), IOC_TYPE_PIOC, 0, 1)>,
				<HPMICRO_PINMUX(HPMICRO_PIN(HPMICRO_PORTY, 1), IOC_TYPE_PIOC, 0, 1)>;
		};
	};

	pinmux_sdxc0_clk_data: pinmux_sdxc0_clk_data {
		group0 {
			pinmux = <HPMICRO_PINMUX(HPMICRO_PIN(HPMICRO_PORTC, 2), IOC_TYPE_IOC, 0, 17)>,
				<HPMICRO_PINMUX(HPMICRO_PIN(HPMICRO_PORTC, 6), IOC_TYPE_IOC, 0, 17)>;
		};
	};

	pinmux_sdxc0_clk_data_pins_width4: pinmux_sdxc0_clk_data_pins_width4 {
		group0 {
			pinmux = <HPMICRO_PINMUX(HPMICRO_PIN(HPMICRO_PORTC, 3), IOC_TYPE_IOC, 0, 17)>,
				<HPMICRO_PINMUX(HPMICRO_PIN(HPMICRO_PORTC, 4), IOC_TYPE_IOC, 0, 17)>,
				<HPMICRO_PINMUX(HPMICRO_PIN(HPMICRO_PORTC, 5), IOC_TYPE_IOC, 0, 17)>,
				<HPMICRO_PINMUX(HPMICRO_PIN(HPMICRO_PORTC, 2), IOC_TYPE_IOC, 0, 17)>,
				<HPMICRO_PINMUX(HPMICRO_PIN(HPMICRO_PORTC, 6), IOC_TYPE_IOC, 0, 17)>;
		};
	};

	pinmux_sdxc0_clk_data_pins_width8: pinmux_sdxc0_clk_data_pins_width8 {
		group0 {
			pinmux = <HPMICRO_PINMUX(HPMICRO_PIN(HPMICRO_PORTC, 8), IOC_TYPE_IOC, 0, 17)>,
				<HPMICRO_PINMUX(HPMICRO_PIN(HPMICRO_PORTC, 9), IOC_TYPE_IOC, 0, 17)>,
				<HPMICRO_PINMUX(HPMICRO_PIN(HPMICRO_PORTC, 10), IOC_TYPE_IOC, 0, 17)>,
				<HPMICRO_PINMUX(HPMICRO_PIN(HPMICRO_PORTC, 11), IOC_TYPE_IOC, 0, 17)>,
				<HPMICRO_PINMUX(HPMICRO_PIN(HPMICRO_PORTC, 2), IOC_TYPE_IOC, 0, 17)>,
				<HPMICRO_PINMUX(HPMICRO_PIN(HPMICRO_PORTC, 6), IOC_TYPE_IOC, 0, 17)>,
				<HPMICRO_PINMUX(HPMICRO_PIN(HPMICRO_PORTC, 3), IOC_TYPE_IOC, 0, 17)>,
				<HPMICRO_PINMUX(HPMICRO_PIN(HPMICRO_PORTC, 4), IOC_TYPE_IOC, 0, 17)>,
				<HPMICRO_PINMUX(HPMICRO_PIN(HPMICRO_PORTC, 5), IOC_TYPE_IOC, 0, 17)>;
		};
	};

	pinmux_sdxc0_cmd_pin_enable_opendrain: pinmux_sdxc0_cmd_pin_enable_opendrain {
		group0 {
			pinmux = <HPMICRO_PINMUX(HPMICRO_PIN(HPMICRO_PORTC, 1), IOC_TYPE_IOC, 0, 17)>;
		};
	};

	pinmux_sdxc0_ds: pinmux_sdxc0_ds {
		group0 {
			pinmux = <HPMICRO_PINMUX(HPMICRO_PIN(HPMICRO_PORTC, 0), IOC_TYPE_IOC, 0, 17)>;
		};
	};

	pinmux_sdxc1_cd: pinmux_sdxc1_cd {
		group0 {
			pinmux = <HPMICRO_PINMUX(HPMICRO_PIN(HPMICRO_PORTD, 5), IOC_TYPE_IOC, 0, 0)>;
		};
	};

	pinmux_sdxc1_clk_data: pinmux_sdxc1_clk_data {
		group0 {
			pinmux = <HPMICRO_PINMUX(HPMICRO_PIN(HPMICRO_PORTC, 16), IOC_TYPE_IOC, 0, 17)>,
				<HPMICRO_PINMUX(HPMICRO_PIN(HPMICRO_PORTC, 17), IOC_TYPE_IOC, 0, 17)>,
				<HPMICRO_PINMUX(HPMICRO_PIN(HPMICRO_PORTC, 15), IOC_TYPE_IOC, 0, 17)>,
				<HPMICRO_PINMUX(HPMICRO_PIN(HPMICRO_PORTC, 14), IOC_TYPE_IOC, 0, 17)>,
				<HPMICRO_PINMUX(HPMICRO_PIN(HPMICRO_PORTC, 12), IOC_TYPE_IOC, 0, 17)>;
		};
	};

	pinmux_sdxc1_cmd: pinmux_sdxc1_cmd {
		group0 {
			pinmux = <HPMICRO_PINMUX(HPMICRO_PIN(HPMICRO_PORTC, 13), IOC_TYPE_IOC, 0, 17)>;
		};
	};

	pinmux_sdxc1_pwr: pinmux_sdxc1_pwr {
		group0 {
			pinmux = <HPMICRO_PINMUX(HPMICRO_PIN(HPMICRO_PORTD, 7), IOC_TYPE_IOC, 0, 0)>;
		};
	};

	pinmux_sdxc1_vsel: pinmux_sdxc1_vsel {
		group0 {
			pinmux = <HPMICRO_PINMUX(HPMICRO_PIN(HPMICRO_PORTD, 12), IOC_TYPE_IOC, 0, 0)>;
		};
	};
};
